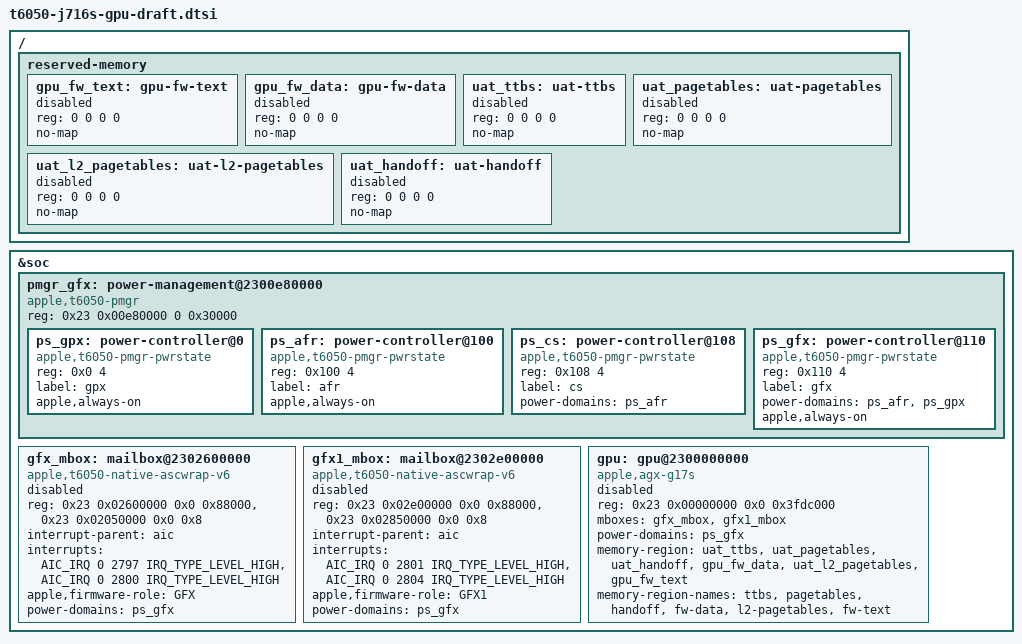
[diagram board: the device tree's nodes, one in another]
// SPDX-License-Identifier: GPL-2.0+ OR MIT
/*
 * DRAFT, not built: the T6050 GPU nodes for the 16-inch M5 Pro (J716s), shaped for
 * aurora-silicon/linux#1012's G17 M5 driver (compatible apple,agx-g17s, the six named memory
 * regions of t604x-j614-j616.dtsi) and for its mailbox driver.
 *
 * Every address is from the J716s runtime ADT (mBoot-20457.41.2 capture), arm-io + 0x2_0000_0000:
 *   sgx          /arm-io/sgx reg[0]        0x23_0000_0000 + 0x3fdc000
 *   gfx-asc      /arm-io/gfx-asc reg[0..1] 0x23_0260_0000 + 0x88000, 0x23_0205_0000 + 0x8
 *   gfx1-asc     /arm-io/gfx1-asc reg[0..1] 0x23_02e0_0000 + 0x88000, 0x23_0285_0000 (+0x60000 in
 *                the ADT; the mailbox driver requires an iop-vbar of exactly 0x8)
 *   interrupts   gfx-asc [2798, 2797, 2800, 2799], gfx1-asc [2802, 2801, 2804, 2803]; the
 *                send-empty / recv-not-empty choice (2797/2800, 2801/2804) is edimoldovan's J714c
 *                mapping, which booted RTKit there.
 *   power        PMGR ps group 3 (pmgr reg[51] 0x23_00e8_0000 + 0x30000): GPX +0x0, AFR +0x100,
 *                CS +0x108 (parent AFR), GFX +0x110 (parents AFR, GPX; notify_pmp, id1 16).
 *
 * The loader (m1n1) must fill, per boot, from the ADT (never hardcode: the firmware moved by
 * 0x8000 between mBoot 41.x and 60.65):
 *   uat-ttbs          sgx gpu-region-base/size            (41.2: 0x10b_fffa_8000 + 0x4000)
 *   uat-pagetables    sgx gfx-shared-region-base/size     (41.2: 0x10b_fff2_8000 + 0x80000)
 *   uat-l2-pagetables sgx gfx-shared-l2-region-base/size  (41.2: 0x10b_fff2_4000 + 0x4000)
 *   uat-handoff       sgx gfx-handoff-base/size           (41.2: 0x10b_fff2_0000 + 0x4000)
 *   gpu-fw-text       gfx-asc segment-ranges[0] (TEXT) start .. gfx1-asc segment-ranges[0] end;
 *                     refuse if not contiguous; 0xa4000 for the G17S build
 *   gpu-fw-data       gfx-asc segment-ranges[1] (DATA) start .. gfx1-asc segment-ranges[2]
 *                     (DATA_SHARED_RO) end; refuse if not contiguous; 0x184000
 * and set status = "okay" on those nodes and on &gpu, plus optionally apple,firmware-version
 * (selection hint only) and apple,leakage-calibration-words (only gates the J714 controller
 * defaults; without it the firmware keeps its default power budget).
 */

/ {
	reserved-memory {
		gpu_fw_text: gpu-fw-text {
			reg = <0 0 0 0>;
			status = "disabled";
			no-map;
		};

		gpu_fw_data: gpu-fw-data {
			reg = <0 0 0 0>;
			status = "disabled";
			no-map;
		};

		uat_ttbs: uat-ttbs {
			reg = <0 0 0 0>;
			status = "disabled";
			no-map;
		};

		uat_pagetables: uat-pagetables {
			reg = <0 0 0 0>;
			status = "disabled";
			no-map;
		};

		uat_l2_pagetables: uat-l2-pagetables {
			reg = <0 0 0 0>;
			status = "disabled";
			no-map;
		};

		uat_handoff: uat-handoff {
			reg = <0 0 0 0>;
			status = "disabled";
			no-map;
		};
	};
};

&soc {
	pmgr_gfx: power-management@2300e80000 {
		compatible = "apple,t6050-pmgr", "apple,pmgr", "syscon", "simple-mfd";
		#address-cells = <1>;
		#size-cells = <1>;
		reg = <0x23 0x00e80000 0 0x30000>;

		ps_gpx: power-controller@0 {
			compatible = "apple,t6050-pmgr-pwrstate", "apple,t8103-pmgr-pwrstate";
			reg = <0x0 4>;
			#power-domain-cells = <0>;
			#reset-cells = <0>;
			label = "gpx";
			apple,always-on;	/* ADT: critical */
		};

		ps_afr: power-controller@100 {
			compatible = "apple,t6050-pmgr-pwrstate", "apple,t8103-pmgr-pwrstate";
			reg = <0x100 4>;
			#power-domain-cells = <0>;
			#reset-cells = <0>;
			label = "afr";
			apple,always-on;	/* ADT: critical */
		};

		ps_cs: power-controller@108 {
			compatible = "apple,t6050-pmgr-pwrstate", "apple,t8103-pmgr-pwrstate";
			reg = <0x108 4>;
			#power-domain-cells = <0>;
			#reset-cells = <0>;
			label = "cs";
			power-domains = <&ps_afr>;
		};

		ps_gfx: power-controller@110 {
			compatible = "apple,t6050-pmgr-pwrstate", "apple,t8103-pmgr-pwrstate";
			reg = <0x110 4>;
			#power-domain-cells = <0>;
			#reset-cells = <0>;
			label = "gfx";
			power-domains = <&ps_afr>, <&ps_gpx>;
			/* As on J616/J700: the loaded firmware lives across sleep. */
			apple,always-on;
		};
	};

	/*
	 * mailbox.c's "apple,t6050-ascwrap-v6" profile (PR #1012 tree, mailbox.c:1641-1657) expects
	 * GFX at 0x8_0260_0000 / vbar 0x8_0205_0000 and GFX1 at 0x8_02e0_0000 / 0x8_0285_0000
	 * (T8140 base + 0x3_8000_0000), not at the J716s
	 * ADT addresses below: probe would fail "GFX ASCWrap v6 resources do not match the SoC".
	 * Needs a native-PA T6050 role table (wrapper 0x23_0260_0000 / vbar 0x23_0205_0000, GFX1
	 * 0x23_02e0_0000 / 0x23_0285_0000) under its own compatible, as edimoldovan did for J714c.
	 */
	gfx_mbox: mailbox@2302600000 {
		compatible = "apple,t6050-native-ascwrap-v6";	/* DRAFT name, see above */
		reg = <0x23 0x02600000 0x0 0x88000>,
		      <0x23 0x02050000 0x0 0x8>;
		reg-names = "wrapper", "iop-vbar";
		interrupt-parent = <&aic>;
		interrupts = <AIC_IRQ 0 2797 IRQ_TYPE_LEVEL_HIGH>,
			     <AIC_IRQ 0 2800 IRQ_TYPE_LEVEL_HIGH>;
		interrupt-names = "send-empty", "recv-not-empty";
		apple,firmware-role = "GFX";
		power-domains = <&ps_gfx>;
		#mbox-cells = <0>;
		status = "disabled";
	};

	gfx1_mbox: mailbox@2302e00000 {
		compatible = "apple,t6050-native-ascwrap-v6";	/* DRAFT name, see above */
		reg = <0x23 0x02e00000 0x0 0x88000>,
		      <0x23 0x02850000 0x0 0x8>;
		reg-names = "wrapper", "iop-vbar";
		interrupt-parent = <&aic>;
		interrupts = <AIC_IRQ 0 2801 IRQ_TYPE_LEVEL_HIGH>,
			     <AIC_IRQ 0 2804 IRQ_TYPE_LEVEL_HIGH>;
		interrupt-names = "send-empty", "recv-not-empty";
		apple,firmware-role = "GFX1";
		power-domains = <&ps_gfx>;
		#mbox-cells = <0>;
		status = "disabled";
	};

	gpu: gpu@2300000000 {
		compatible = "apple,agx-g17s";
		/* The G17 path maps only "sgx" (regs.rs:585); the ASC wrappers belong to the mailboxes. */
		reg = <0x23 0x00000000 0x0 0x3fdc000>;
		reg-names = "sgx";
		mboxes = <&gfx_mbox>, <&gfx1_mbox>;
		power-domains = <&ps_gfx>;
		memory-region = <&uat_ttbs>, <&uat_pagetables>, <&uat_handoff>,
				<&gpu_fw_data>, <&uat_l2_pagetables>, <&gpu_fw_text>;
		memory-region-names = "ttbs", "pagetables", "handoff", "fw-data",
				      "l2-pagetables", "fw-text";
		/* No operating-points-v2: the M5 path takes its tables from the board (mod.rs:1512). */
		status = "disabled";
	};
};
